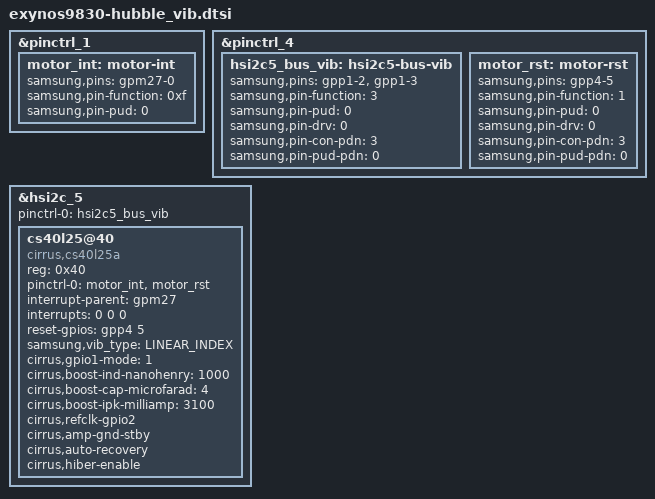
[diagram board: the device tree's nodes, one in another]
/*
 * SAMSUNG EXYNOS9830 board device tree source
 *
 * Copyright (c) 2019 Samsung Electronics Co., Ltd.
 *		http://www.samsung.com
 *
 * This program is free software; you can redistribute it and/or modify
 * it under the terms of the GNU General Public License version 2 as
 * published by the Free Software Foundation.
*/

&pinctrl_1 {
	motor_int: motor-int {
		samsung,pins ="gpm27-0";
		samsung,pin-function = <0xf>;
		samsung,pin-pud = <0>;
	};
};

&pinctrl_4 {
	hsi2c5_bus_vib: hsi2c5-bus-vib {
		samsung,pins = "gpp1-2", "gpp1-3";
		samsung,pin-function = <3>;
		samsung,pin-pud = <0>;
		samsung,pin-drv = <0>;
		samsung,pin-con-pdn = <3>;
		samsung,pin-pud-pdn = <0>;
	};

	motor_rst: motor-rst {
		samsung,pins = "gpp4-5";
		samsung,pin-function = <1>;
		samsung,pin-pud = <0>;
		samsung,pin-drv = <0>;
		samsung,pin-con-pdn = <3>;
		samsung,pin-pud-pdn = <0>;
	};
};

&hsi2c_5 {
	status = "okay";
	pinctrl-0 = <&hsi2c5_bus_vib>;
	cs40l25@40 {
		compatible = "cirrus,cs40l25a";
		reg = <0x40>;
		pinctrl-names = "default";
		pinctrl-0 = <&motor_int &motor_rst>;
		interrupt-parent = <&gpm27>;
		interrupts = <0 0 0>;
		reset-gpios = <&gpp4 5 0>;
		samsung,vib_type = "LINEAR_INDEX";
		cirrus,gpio1-mode = <1>;
		cirrus,boost-ind-nanohenry = <1000>;
		cirrus,boost-cap-microfarad = <4>;
		cirrus,boost-ipk-milliamp = <3100>;
		cirrus,refclk-gpio2;
		cirrus,amp-gnd-stby;
		cirrus,auto-recovery;
		cirrus,hiber-enable;
	};
};
